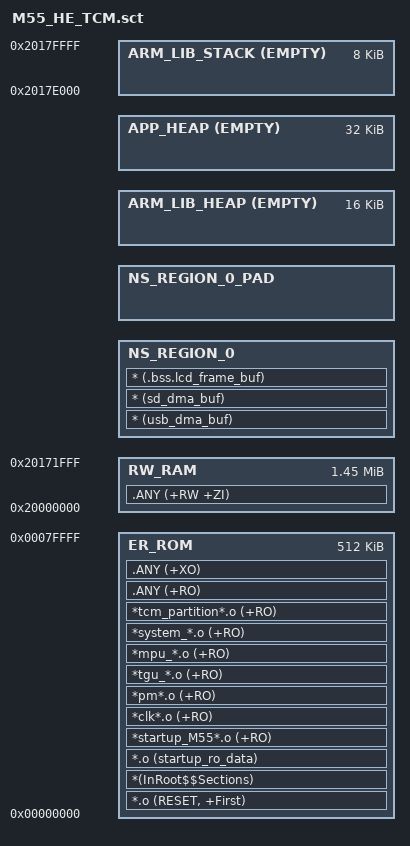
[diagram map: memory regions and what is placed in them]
#! armclang -E --target=arm-arm-none-eabi -mcpu=cortex-m55 -xc
; command above MUST be in first line (no comment above!)
/*
;-------- <<< Use Configuration Wizard in Context Menu >>> -------------------
*/
/* On chip RAM Regions */
#define SRAM4_BASE                0x58000000
#define SRAM4_SIZE                0x00080000    /* 512KB */
#define SRAM5_BASE                0x58800000
#define SRAM5_SIZE                0x00180000    /* 1536KB */

/*--------------------- ITCM Configuration ----------------------------------
; <h> ITCM Configuration
;   <o0> ITCM Base Address <0x0-0xFFFFFFFF:8>
;   <o1> ITCM Size (in Bytes) <0x0-0xFFFFFFFF:8>
; </h>
 *----------------------------------------------------------------------------*/
/* SRAM4 is mapped as ITCM in M55-HE */
#define __ROM_BASE      0x00000000
#define __ROM_SIZE      SRAM4_SIZE

/*--------------------- DTCM Configuration ---------------------------
; <h> DTCM Configuration
;   <o0> DTCM Base Address    <0x0-0xFFFFFFFF:8>
;   <o1> DTCM Size (in Bytes) <0x0-0xFFFFFFFF:8>
; </h>
 *----------------------------------------------------------------------------*/
/* SRAM5 is mapped as DTCM in M55-HE */
#define __RAM_BASE      0x20000000
#define __RAM_SIZE      SRAM5_SIZE

/*--------------------- Stack / Heap Configuration ---------------------------
; <h> Stack / Heap Configuration
;   <o0> Stack Size (in Bytes) <0x0-0xFFFFFFFF:8>
;   <o1> Heap Size (in Bytes) <0x0-0xFFFFFFFF:8>
;   <o2> App Heap Size (in Bytes) <0x0-0xFFFFFFFF:8>
; </h>
 *----------------------------------------------------------------------------*/
#define __STACK_SIZE    0x00002000
#define __HEAP_SIZE     0x00004000
#define __APP_HEAP_SIZE 0x00008000

/*
;------------- <<< end of configuration section >>> ---------------------------
*/


/*----------------------------------------------------------------------------
  User Stack & Heap boundary definition
 *----------------------------------------------------------------------------*/
#define __STACK_TOP     (__RAM_BASE + __RAM_SIZE)    /* starts at end of RAM */
#define __HEAP_BASE     (AlignExpr(+0, 8))           /* starts after RW_RAM section, 8 byte aligned */
#define __APP_HEAP_BASE (AlignExpr(+0, 8))           /* starts after HEAP, 8 byte aligned */


/*----------------------------------------------------------------------------
  Scatter File Definitions definition
 *----------------------------------------------------------------------------*/
#define __RO_BASE       __ROM_BASE
#define __RO_SIZE       __ROM_SIZE

#define __RW_BASE       __RAM_BASE
#define __RW_SIZE      (__RAM_SIZE - __STACK_SIZE - __HEAP_SIZE - __APP_HEAP_SIZE)

#define TGU_BLOCK_SIZE  131072

LR_ROM __RO_BASE __RO_SIZE  {                       ; load region size_region
  ER_ROM __RO_BASE __RO_SIZE  {                     ; load address = execution address
   *.o (RESET, +First)
   *(InRoot$$Sections)
   *.o (startup_ro_data)

   ; These should be part of primary load region
   *startup_M55*.o (+RO)
   *clk*.o (+RO)
   *pm*.o (+RO)
   *tgu_*.o (+RO)
   *mpu_*.o (+RO)
   *system_*.o (+RO)
   *tcm_partition*.o (+RO)

   .ANY (+RO)
   .ANY (+XO)
  }

  RW_RAM __RW_BASE __RW_SIZE  {                     ; RW data
   .ANY (+RW +ZI)
  }

  NS_REGION_0  (AlignExpr(+0, TGU_BLOCK_SIZE)) { ; Non secure region 0
    * (usb_dma_buf)
    * (sd_dma_buf)
    * (.bss.lcd_frame_buf)
  }

  NS_REGION_0_PAD  (AlignExpr(ImageLimit(NS_REGION_0), TGU_BLOCK_SIZE)) { ; Non secure region 0 Padding
  }
  ScatterAssert((ImageBase(NS_REGION_0_PAD) - ImageBase(NS_REGION_0) + ImageLength(RW_RAM)) < __RW_SIZE)

#if __HEAP_SIZE > 0
  ARM_LIB_HEAP  __HEAP_BASE EMPTY  __HEAP_SIZE  {   ; Reserve empty region for heap
  }
#endif

  APP_HEAP  __APP_HEAP_BASE EMPTY  __APP_HEAP_SIZE {; Reserve empty region for application heap
  }

  ARM_LIB_STACK __STACK_TOP EMPTY -__STACK_SIZE {   ; Reserve empty region for stack
  }

}
